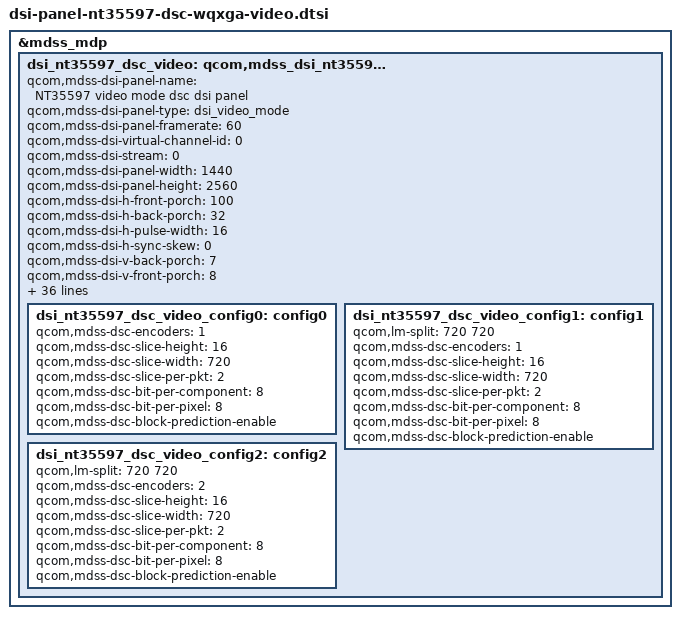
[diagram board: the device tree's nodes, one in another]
/* Copyright (c) 2015-2016, The Linux Foundation. All rights reserved.
 *
 * This program is free software; you can redistribute it and/or modify
 * it under the terms of the GNU General Public License version 2 and
 * only version 2 as published by the Free Software Foundation.
 *
 * This program is distributed in the hope that it will be useful,
 * but WITHOUT ANY WARRANTY; without even the implied warranty of
 * MERCHANTABILITY or FITNESS FOR A PARTICULAR PURPOSE.  See the
 * GNU General Public License for more details.
 */

&mdss_mdp {
	dsi_nt35597_dsc_video: qcom,mdss_dsi_nt35597_dsc_wqxga_video {
		qcom,mdss-dsi-panel-name = "NT35597 video mode dsc dsi panel";
		qcom,mdss-dsi-panel-type = "dsi_video_mode";
		qcom,mdss-dsi-panel-framerate = <60>;
		qcom,mdss-dsi-virtual-channel-id = <0>;
		qcom,mdss-dsi-stream = <0>;
		qcom,mdss-dsi-panel-width = <1440>;
		qcom,mdss-dsi-panel-height = <2560>;
		qcom,mdss-dsi-h-front-porch = <100>;
		qcom,mdss-dsi-h-back-porch = <32>;
		qcom,mdss-dsi-h-pulse-width = <16>;
		qcom,mdss-dsi-h-sync-skew = <0>;
		qcom,mdss-dsi-v-back-porch = <7>;
		qcom,mdss-dsi-v-front-porch = <8>;
		qcom,mdss-dsi-v-pulse-width = <1>;
		qcom,mdss-dsi-bpp = <24>;
		qcom,mdss-dsi-underflow-color = <0xff>;
		qcom,mdss-dsi-border-color = <0>;
		qcom,mdss-dsi-panel-hdr-enabled;
		qcom,mdss-dsi-panel-hdr-color-primaries = <14500 15500 32000
			17000 15500 30000 8000 3000>;
		qcom,mdss-dsi-panel-peak-brightness = <4200000>;
		qcom,mdss-dsi-panel-blackness-level = <3230>;
		qcom,mdss-dsi-on-command = [15 01 00 00 00 00 02 ff 10
			15 01 00 00 00 00 02 fb 01
			15 01 00 00 00 00 02 ba 03
			15 01 00 00 00 00 02 e5 01
			15 01 00 00 00 00 02 b0 03
			39 01 00 00 00 00 06 3B 03 08 08 2e 64
			15 01 00 00 00 00 02 ff 28
			15 01 00 00 00 00 02 7a 02
			15 01 00 00 00 00 02 fb 01
			15 01 00 00 00 00 02 ff 10
			15 01 00 00 00 00 02 fb 01
			15 01 00 00 00 00 02 c0 03
			15 01 00 00 00 00 02 bb 03
			15 01 00 00 00 00 02 ff e0
			15 01 00 00 00 00 02 fb 01
			15 01 00 00 00 00 02 6b 3d
			15 01 00 00 00 00 02 6c 3d
			15 01 00 00 00 00 02 6d 3d
			15 01 00 00 00 00 02 6e 3d
			15 01 00 00 00 00 02 6f 3d
			15 01 00 00 00 00 02 35 02
			15 01 00 00 00 00 02 36 72
			15 01 00 00 00 00 02 37 10
			15 01 00 00 00 00 02 08 c0
			15 01 00 00 00 00 02 ff 10
			05 01 00 00 a0 00 01 11
			05 01 00 00 00 00 01 29
			07 01 00 00 0a 00 01 01];

		qcom,mdss-dsi-off-command = [05 01 00 00 0a 00 02 28 00
				 05 01 00 00 0a 00 02 10 00];
		qcom,mdss-dsi-on-command-state = "dsi_lp_mode";
		qcom,mdss-dsi-off-command-state = "dsi_hs_mode";
		qcom,mdss-dsi-h-sync-pulse = <0>;
		qcom,mdss-dsi-traffic-mode = "non_burst_sync_event";
		qcom,mdss-dsi-bllp-eof-power-mode;
		qcom,mdss-dsi-bllp-power-mode;
		qcom,mdss-dsi-lane-0-state;
		qcom,mdss-dsi-lane-1-state;
		qcom,mdss-dsi-lane-2-state;
		qcom,mdss-dsi-lane-3-state;
		qcom,mdss-dsi-panel-timings = [e2 36 24 00 66 6a 28 38 2a 03 04 00];
		qcom,mdss-dsi-t-clk-post = <0xb>;
		qcom,mdss-dsi-t-clk-pre = <0x24>;
		qcom,mdss-dsi-dma-trigger = "trigger_sw";
		qcom,mdss-dsi-mdp-trigger = "none";
		qcom,mdss-dsi-reset-sequence = <1 10>, <0 10>, <1 10>;
		qcom,mdss-pan-physical-width-dimension = <74>;
		qcom,mdss-pan-physical-height-dimension = <131>;

		qcom,compression-mode = "dsc";
		qcom,config-select = <&dsi_nt35597_dsc_video_config0>;

		dsi_nt35597_dsc_video_config0: config0 {
			qcom,mdss-dsc-encoders = <1>;
			qcom,mdss-dsc-slice-height = <16>;
			qcom,mdss-dsc-slice-width = <720>;
			qcom,mdss-dsc-slice-per-pkt = <2>;

			qcom,mdss-dsc-bit-per-component = <8>;
			qcom,mdss-dsc-bit-per-pixel = <8>;
			qcom,mdss-dsc-block-prediction-enable;
		};

		dsi_nt35597_dsc_video_config1: config1 {
			qcom,lm-split = <720 720>;
			qcom,mdss-dsc-encoders = <1>; /* 3D Mux */
			qcom,mdss-dsc-slice-height = <16>;
			qcom,mdss-dsc-slice-width = <720>;
			qcom,mdss-dsc-slice-per-pkt = <2>;

			qcom,mdss-dsc-bit-per-component = <8>;
			qcom,mdss-dsc-bit-per-pixel = <8>;
			qcom,mdss-dsc-block-prediction-enable;
		};

		dsi_nt35597_dsc_video_config2: config2 {
			qcom,lm-split = <720 720>;
			qcom,mdss-dsc-encoders = <2>; /* DSC Merge */
			qcom,mdss-dsc-slice-height = <16>;
			qcom,mdss-dsc-slice-width = <720>;
			qcom,mdss-dsc-slice-per-pkt = <2>;

			qcom,mdss-dsc-bit-per-component = <8>;
			qcom,mdss-dsc-bit-per-pixel = <8>;
			qcom,mdss-dsc-block-prediction-enable;
		};
	};
};
